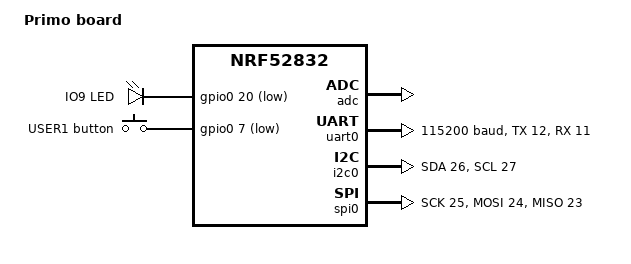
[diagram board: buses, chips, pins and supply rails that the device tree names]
/*
 * Copyright (c) 2017 Shawn Nock <shawn@monadnock.ca>
 * Copyright (c) 2017 Linaro Limited
 * Copyright (c) 2018 dog hunter LLC and the Linino community
 *
 * Linino.org is a dog hunter sponsored community project
 *
 * This file comes from nrf52_pca10040.dts and was modified by
 * Davide Ciminaghi <davide@linino.org> and Jeff Wu <jeff@doghunter.org>
 *
 * SPDX-License-Identifier: Apache-2.0
 */

/dts-v1/;
#include <nordic/nrf52832_qfaa.dtsi>

/ {
	model = "Primo board";
	compatible = "doghunter,primo", "nordic,nrf52832-qfaa",
		     "nordic,nrf52832";

	chosen {
		zephyr,console = &uart0;
#ifdef CONFIG_MCUMGR_SMP_UART
		zephyr,uart-mcumgr = &uart0;
#endif
		zephyr,sram = &sram0;
		zephyr,flash = &flash0;
	};

	leds {
		compatible = "gpio-leds";
		led0: led_0 {
			gpios = <&gpio0 20 GPIO_INT_ACTIVE_LOW>;
			label = "IO9 LED";
		};
	};

	buttons {
		compatible = "gpio-keys";
		button0: button_0 {
			gpios = <&gpio0 7 GPIO_INT_ACTIVE_LOW>;
			label = "USER1 button";
		};
	};

	/* These aliases are provided for compatibility with samples */
	aliases {
		led0 = &led0;
		sw0 = &button0;
	};
};

&adc {
	status ="ok";
};

&gpiote {
	status ="ok";
};

&gpio0 {
	status ="ok";
};

&uart0 {
	status = "ok";
	compatible = "nordic,nrf-uart";
	current-speed = <115200>;
	/* nRF52_TX1 */
	tx-pin = <12>;
	/* nRF52_RX1 */
	rx-pin = <11>;
};

&i2c0 {
	status = "ok";
	/* nRF52_SDA */
	sda-pin = <26>;
	/* nRF52_SCL */
	scl-pin = <27>;
};

&i2c1 {
	status = "disabled";
};

/*
 * CS -> ESP_GPIO15 -> nRF52_TX2 -> P0.06
 * MOSI -> ESP_GPIO12 -> 12 -> P0.24
 * MISO -> ESP_GPIO13 -> 11 -> P0.23
 * CLK -> ESP_GPIO14 -> 13 -> P0.25
 */
&spi0 {
	status = "ok";
	csn-pin = <6>;
	mosi-pin = <24>;
	miso-pin = <23>;
	sck-pin = <25>;
};

&flash0 {
	/*
	 * For more information, see:
	 * http://docs.zephyrproject.org/latest/devices/dts/flash_partitions.html
	 */
	partitions {
		compatible = "fixed-partitions";
		#address-cells = <1>;
		#size-cells = <1>;

		boot_partition: partition@0 {
			label = "mcuboot";
			reg = <0x00000000 0xc000>;
		};
		slot0_partition: partition@c000 {
			label = "image-0";
			reg = <0x0000C000 0x32000>;
		};
		slot1_partition: partition@3e000 {
			label = "image-1";
			reg = <0x0003E000 0x32000>;
		};
		scratch_partition: partition@70000 {
			label = "image-scratch";
			reg = <0x00070000 0xa000>;
		};

#if defined(CONFIG_FS_FLASH_STORAGE_PARTITION)
		storage_partition: partition@7a000 {
			label = "storage";
			reg = <0x0007a000 0x00006000>;
		};
#endif
	};
};
